VERSION ""

NS_ :

BS_:

BU_: MASTER BRIDGE MOTOR SENSOR GPS

BO_ 103 BRIDGE_NODE: 1 BRIDGE
 SG_ BRIDGE_START_cmd : 0|1@1+ (1,0) [0|1] "" MASTER

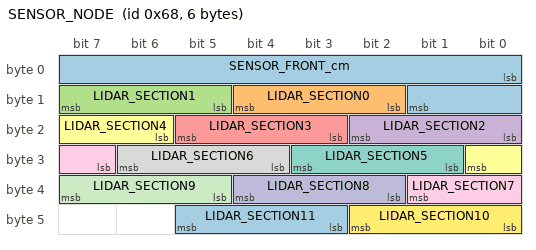
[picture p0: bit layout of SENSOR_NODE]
BO_ 104 SENSOR_NODE: 6 SENSOR
 SG_ SENSOR_FRONT_cm : 0|10@1+ (1,0) [0|645] "cm" MASTER,MOTOR
 SG_ LIDAR_SECTION0 : 10|3@1+ (1,0) [0|7] "" MASTER
 SG_ LIDAR_SECTION1 : 13|3@1+ (1,0) [0|7] "" MASTER
 SG_ LIDAR_SECTION2 : 16|3@1+ (1,0) [0|7] "" MASTER
 SG_ LIDAR_SECTION3 : 19|3@1+ (1,0) [0|7] "" MASTER
 SG_ LIDAR_SECTION4 : 22|3@1+ (1,0) [0|7] "" MASTER
 SG_ LIDAR_SECTION5 : 25|3@1+ (1,0) [0|7] "" MASTER
 SG_ LIDAR_SECTION6 : 28|3@1+ (1,0) [0|7] "" MASTER
 SG_ LIDAR_SECTION7 : 31|3@1+ (1,0) [0|7] "" MASTER
 SG_ LIDAR_SECTION8 : 34|3@1+ (1,0) [0|7] "" MASTER
 SG_ LIDAR_SECTION9 : 37|3@1+ (1,0) [0|7] "" MASTER
 SG_ LIDAR_SECTION10 : 40|3@1+ (1,0) [0|7] "" MASTER
 SG_ LIDAR_SECTION11 : 43|3@1+ (1,0) [0|7] "" MASTER

BO_ 105 CAR_CONTROL: 1 MASTER
 SG_ MOTOR_DRIVE_cmd : 0|3@1+ (1,0) [0|0] "" MOTOR
 SG_ MOTOR_STEER_cmd : 3|3@1+ (1,0) [0|0] "" MOTOR

BO_ 106 MOTOR_NODE: 1 MOTOR
 SG_ MOTOR_SPEED_mph : 0|8@1+ (0.1,0) [0.0|15.0] "mph" MASTER,BRIDGE

BO_ 107 BRIDGE_CHECKPOINTS: 8 BRIDGE
 SG_ CHECKPOINT_LAT_deg : 0|28@1+ (0.000001,-90.000000) [-90|90] "Degrees" MASTER,GPS
 SG_ CHECKPOINT_LONG_deg : 28|29@1+ (0.000001,-180.000000) [-180|180] "Degrees" MASTER,GPS

BO_ 108 GPS_LOCATION: 8 GPS
 SG_ CURRENT_LAT_deg : 0|28@1+ (0.000001,-90.000000) [-90|90] "Degrees" MASTER,BRIDGE,MOTOR
 SG_ CURRENT_LONG_deg : 28|29@1+ (0.000001,-180.000000) [-180|180] "Degrees" MASTER,BRIDGE,MOTOR

BO_ 109 COMPASS: 8 GPS
 SG_ CMP_HEADING_deg : 0|12@1+ (0.1,0) [0|359.9] "Degrees" MASTER,BRIDGE,MOTOR
 SG_ CMP_BEARING_deg : 12|12@1+ (0.1,0) [0|359.9] "Degrees" MASTER,BRIDGE,MOTOR

BO_ 110 MASTER_HEARTBEAT: 1 MASTER
 SG_ MASTER_hbt : 0|1@1+ (1,0) [0|1] "" SENSOR,MOTOR,BRIDGE,GPS

BO_ 111 SENSOR_HEARTBEAT: 1 SENSOR
 SG_ SENSOR_hbt : 0|1@1+ (1,0) [0|1] "" MASTER

BO_ 112 MOTOR_HEARTBEAT: 1 MOTOR
 SG_ MOTOR_hbt : 0|1@1+ (1,0) [0|1] "" MASTER

BO_ 113 GPS_HEARTBEAT: 1 GPS
 SG_ GPS_hbt : 0|1@1+ (1,0) [0|1] "" MASTER

BO_ 114 BRIDGE_HEARTBEAT: 1 BRIDGE
 SG_ BRIDGE_hbt : 0|1@1+ (1,0) [0|1] "" MASTER

CM_ BU_ MASTER "The driver controller driving the car";
CM_ BU_ MOTOR "The motor controller of the car";
CM_ BU_ SENSOR "The sensor controller of the car";
CM_ BU_ BRIDGE "The bridge controller of the car";
CM_ BU_ GPS "The GPS controller of the car";
CM_ BO_ 100 "Sync message used to synchronize the controllers";

BA_DEF_DEF_ "BusType" "CAN";
BA_DEF_DEF_ "FieldType" "";
BA_DEF_DEF_ "GenMsgCycleTime" 0;

BA_ "GenMsgCycleTime" BO_ 500 100;
BA_ "GenMsgCycleTime" BO_ 100 1000;
BA_ "GenMsgCycleTime" BO_ 101 100;
BA_ "GenMsgCycleTime" BO_ 400 100;
BA_ "GenMsgCycleTime" BO_ 200 100;
BA_ "FieldType" SG_ 105 MOTOR_DRIVE_cmd "MOTOR_DRIVE_cmd";
BA_ "FieldType" SG_ 105 MOTOR_STEER_cmd "MOTOR_STEER_cmd";

VAL_ 105 MOTOR_DRIVE_cmd 2 "MOTOR_STOP" 1 "MOTOR_REV" 3 "MOTOR_FWD_SLOW" 4 "MOTOR_FWD_MED" 5 "MOTOR_FWD_FAST" ;
VAL_ 105 MOTOR_STEER_cmd 2 "MOTOR_DONT_STEER" 1 "MOTOR_STEER_SLIGHT_LEFT" 0 "MOTOR_STEER_FULL_LEFT" 3 "MOTOR_STEER_SLIGHT_RIGHT" 4 "MOTOR_STEER_FULL_RIGHT" ;
